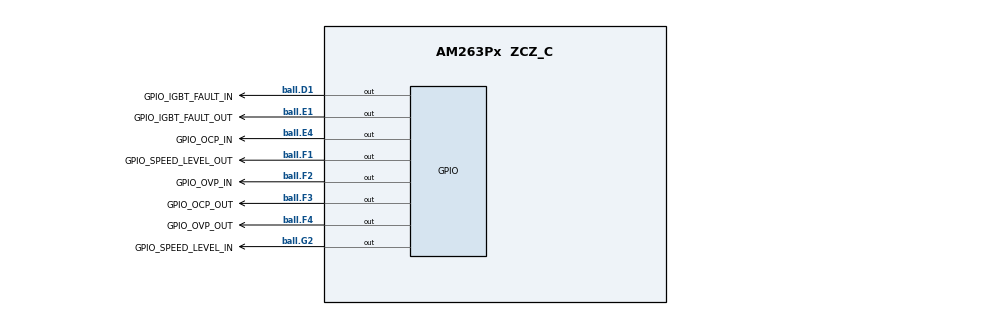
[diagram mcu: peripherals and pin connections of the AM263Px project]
/**
 * These arguments were used when this file was generated. They will be automatically applied on subsequent loads
 * via the GUI or CLI. Run CLI with '--help' for additional information on how to override these arguments.
 * @cliArgs --device "AM263Px" --package "ZCZ_C" --part "AM263P1" --context "r5fss0-0" --product "MCU_PLUS_SDK@07.03.01"
 * @versions {"tool":"1.15.0+2826"}
 */

/**
 * Import the modules used in this configuration.
 */
const epwm       = scripting.addModule("/drivers/epwm/epwm", {}, false);
const epwm1      = epwm.addInstance();
const epwm2      = epwm.addInstance();
const epwm3      = epwm.addInstance();
const gpio       = scripting.addModule("/drivers/gpio/gpio", {}, false);
const gpio1      = gpio.addInstance();
const gpio2      = gpio.addInstance();
const gpio3      = gpio.addInstance();
const gpio4      = gpio.addInstance();
const gpio5      = gpio.addInstance();
const gpio6      = gpio.addInstance();
const gpio7      = gpio.addInstance();
const gpio8      = gpio.addInstance();
const debug_log  = scripting.addModule("/kernel/dpl/debug_log");
const mpu_armv7  = scripting.addModule("/kernel/dpl/mpu_armv7", {}, false);
const mpu_armv71 = mpu_armv7.addInstance();
const mpu_armv72 = mpu_armv7.addInstance();
const mpu_armv73 = mpu_armv7.addInstance();
const mpu_armv74 = mpu_armv7.addInstance();
const epwm_xbar  = scripting.addModule("/xbar/epwm_xbar/epwm_xbar", {}, false);
const epwm_xbar1 = epwm_xbar.addInstance();
const epwm_xbar2 = epwm_xbar.addInstance();
const epwm_xbar3 = epwm_xbar.addInstance();
const epwm_xbar4 = epwm_xbar.addInstance();
const epwm_xbar5 = epwm_xbar.addInstance();
const epwm_xbar6 = epwm_xbar.addInstance();
const epwm_xbar7 = epwm_xbar.addInstance();
const epwm_xbar8 = epwm_xbar.addInstance();
const int_xbar   = scripting.addModule("/xbar/int_xbar/int_xbar", {}, false);
const int_xbar1  = int_xbar.addInstance();

/**
 * Write custom configuration values to the imported modules.
 */
epwm1.epwmTimebase_emulationMode                               = "EPWM_EMULATION_FREE_RUN";
epwm1.epwmTimebase_period                                      = 10000;
epwm1.epwmTimebase_counterMode                                 = "EPWM_COUNTER_MODE_UP";
epwm1.epwmTimebase_syncOutPulseMode                            = ["EPWM_SYNC_OUT_PULSE_ON_ALL"];
epwm1.epwmCounterCompare_cmpA                                  = 7000;
epwm1.epwmCounterCompare_cmpB                                  = 7000;
epwm1.epwmActionQualifier_EPWM_AQ_OUTPUT_A_usedEvents          = ["EPWM_AQ_OUTPUT_ON_TIMEBASE_UP_CMPA","EPWM_AQ_OUTPUT_ON_TIMEBASE_ZERO"];
epwm1.epwmActionQualifier_EPWM_AQ_OUTPUT_B_usedEvents          = ["EPWM_AQ_OUTPUT_ON_TIMEBASE_UP_CMPB","EPWM_AQ_OUTPUT_ON_TIMEBASE_ZERO"];
epwm1.epwmActionQualifier_EPWM_AQ_OUTPUT_A_ON_TIMEBASE_ZERO    = "EPWM_AQ_OUTPUT_HIGH";
epwm1.epwmActionQualifier_EPWM_AQ_OUTPUT_A_ON_TIMEBASE_UP_CMPA = "EPWM_AQ_OUTPUT_LOW";
epwm1.epwmActionQualifier_EPWM_AQ_OUTPUT_B_ON_TIMEBASE_ZERO    = "EPWM_AQ_OUTPUT_LOW";
epwm1.epwmActionQualifier_EPWM_AQ_OUTPUT_B_ON_TIMEBASE_UP_CMPB = "EPWM_AQ_OUTPUT_HIGH";
epwm1.epwmEventTrigger_enableInterrupt                         = true;
epwm1.epwmEventTrigger_interruptEventCount                     = "1";
epwm1.epwmTripZone_EPWM_TZ_ACTION_EVENT_DCAEVT1                = "EPWM_TZ_ACTION_HIGH";
epwm1.epwmTripZone_EPWM_TZ_ACTION_EVENT_DCAEVT2                = "EPWM_TZ_ACTION_LOW";
epwm1.epwmTripZone_EPWM_TZ_ACTION_EVENT_DCBEVT1                = "EPWM_TZ_ACTION_HIGH";
epwm1.epwmTripZone_EPWM_TZ_ACTION_EVENT_DCBEVT2                = "EPWM_TZ_ACTION_LOW";
epwm1.epwmDigitalCompare_EPWM_TZ_DC_OUTPUT_A1                  = "EPWM_TZ_EVENT_DCXH_HIGH";
epwm1.epwmDigitalCompare_EPWM_TZ_DC_OUTPUT_A2                  = "EPWM_TZ_EVENT_DCXL_HIGH";
epwm1.epwmDigitalCompare_EPWM_TZ_DC_OUTPUT_B1                  = "EPWM_TZ_EVENT_DCXH_HIGH";
epwm1.epwmDigitalCompare_EPWM_TZ_DC_OUTPUT_B2                  = "EPWM_TZ_EVENT_DCXL_HIGH";
epwm1.epwmDigitalCompare_EPWM_DC_TYPE_DCAH                     = "EPWM_DC_TRIP_TRIPIN5";
epwm1.epwmDigitalCompare_EPWM_DC_TYPE_DCAL                     = "EPWM_DC_TRIP_TRIPIN6";
epwm1.epwmDigitalCompare_EPWM_DC_TYPE_DCBH                     = "EPWM_DC_TRIP_TRIPIN7";
epwm1.epwmDigitalCompare_EPWM_DC_TYPE_DCBL                     = "EPWM_DC_TRIP_TRIPIN8";
epwm1.$name                                                    = "CONFIG_PWM0";
epwm1.epwmDeadband_polarityFED                                 = "EPWM_DB_POLARITY_ACTIVE_LOW";
epwm1.epwmDeadband_enableRED                                   = true;
epwm1.epwmDeadband_enableFED                                   = true;
epwm1.epwmDeadband_delayRED                                    = 100;
epwm1.epwmDeadband_delayFED                                    = 100;
epwm1.EPWM.$assign                                             = "EPWM0";

epwm2.$name                                                    = "CONFIG_PWM1";
epwm2.epwmTimebase_counterMode                                 = "EPWM_COUNTER_MODE_UP";
epwm2.epwmTimebase_period                                      = 10000;
epwm2.epwmCounterCompare_cmpA                                  = 7000;
epwm2.epwmCounterCompare_cmpB                                  = 7000;
epwm2.epwmActionQualifier_EPWM_AQ_OUTPUT_A_usedEvents          = ["EPWM_AQ_OUTPUT_ON_TIMEBASE_UP_CMPA","EPWM_AQ_OUTPUT_ON_TIMEBASE_ZERO"];
epwm2.epwmActionQualifier_EPWM_AQ_OUTPUT_B_usedEvents          = ["EPWM_AQ_OUTPUT_ON_TIMEBASE_UP_CMPB","EPWM_AQ_OUTPUT_ON_TIMEBASE_ZERO"];
epwm2.epwmActionQualifier_EPWM_AQ_OUTPUT_A_ON_TIMEBASE_ZERO    = "EPWM_AQ_OUTPUT_HIGH";
epwm2.epwmActionQualifier_EPWM_AQ_OUTPUT_A_ON_TIMEBASE_UP_CMPA = "EPWM_AQ_OUTPUT_LOW";
epwm2.epwmActionQualifier_EPWM_AQ_OUTPUT_B_ON_TIMEBASE_ZERO    = "EPWM_AQ_OUTPUT_LOW";
epwm2.epwmActionQualifier_EPWM_AQ_OUTPUT_B_ON_TIMEBASE_UP_CMPB = "EPWM_AQ_OUTPUT_HIGH";
epwm2.epwmTripZone_EPWM_TZ_ACTION_EVENT_DCAEVT1                = "EPWM_TZ_ACTION_HIGH";
epwm2.epwmTripZone_EPWM_TZ_ACTION_EVENT_DCAEVT2                = "EPWM_TZ_ACTION_LOW";
epwm2.epwmTripZone_EPWM_TZ_ACTION_EVENT_DCBEVT1                = "EPWM_TZ_ACTION_HIGH";
epwm2.epwmTripZone_EPWM_TZ_ACTION_EVENT_DCBEVT2                = "EPWM_TZ_ACTION_LOW";
epwm2.epwmDigitalCompare_EPWM_TZ_DC_OUTPUT_A1                  = "EPWM_TZ_EVENT_DCXH_HIGH";
epwm2.epwmDigitalCompare_EPWM_TZ_DC_OUTPUT_A2                  = "EPWM_TZ_EVENT_DCXL_HIGH";
epwm2.epwmDigitalCompare_EPWM_TZ_DC_OUTPUT_B1                  = "EPWM_TZ_EVENT_DCXH_HIGH";
epwm2.epwmDigitalCompare_EPWM_TZ_DC_OUTPUT_B2                  = "EPWM_TZ_EVENT_DCXL_HIGH";
epwm2.epwmDigitalCompare_EPWM_DC_TYPE_DCAH                     = "EPWM_DC_TRIP_TRIPIN5";
epwm2.epwmDigitalCompare_EPWM_DC_TYPE_DCAL                     = "EPWM_DC_TRIP_TRIPIN6";
epwm2.epwmDigitalCompare_EPWM_DC_TYPE_DCBH                     = "EPWM_DC_TRIP_TRIPIN7";
epwm2.epwmDigitalCompare_EPWM_DC_TYPE_DCBL                     = "EPWM_DC_TRIP_TRIPIN8";
epwm2.epwmDeadband_polarityFED                                 = "EPWM_DB_POLARITY_ACTIVE_LOW";
epwm2.epwmDeadband_enableRED                                   = true;
epwm2.epwmDeadband_enableFED                                   = true;
epwm2.epwmDeadband_delayRED                                    = 100;
epwm2.epwmDeadband_delayFED                                    = 100;
epwm2.EPWM.$assign                                             = "EPWM1";

epwm3.$name                                                    = "CONFIG_PWM2";
epwm3.epwmTimebase_counterMode                                 = "EPWM_COUNTER_MODE_UP";
epwm3.epwmTimebase_period                                      = 10000;
epwm3.epwmCounterCompare_cmpA                                  = 7000;
epwm3.epwmCounterCompare_cmpB                                  = 7000;
epwm3.epwmActionQualifier_EPWM_AQ_OUTPUT_A_usedEvents          = ["EPWM_AQ_OUTPUT_ON_TIMEBASE_UP_CMPA","EPWM_AQ_OUTPUT_ON_TIMEBASE_ZERO"];
epwm3.epwmActionQualifier_EPWM_AQ_OUTPUT_B_usedEvents          = ["EPWM_AQ_OUTPUT_ON_TIMEBASE_UP_CMPB","EPWM_AQ_OUTPUT_ON_TIMEBASE_ZERO"];
epwm3.epwmActionQualifier_EPWM_AQ_OUTPUT_A_ON_TIMEBASE_ZERO    = "EPWM_AQ_OUTPUT_HIGH";
epwm3.epwmActionQualifier_EPWM_AQ_OUTPUT_A_ON_TIMEBASE_UP_CMPA = "EPWM_AQ_OUTPUT_LOW";
epwm3.epwmActionQualifier_EPWM_AQ_OUTPUT_B_ON_TIMEBASE_ZERO    = "EPWM_AQ_OUTPUT_LOW";
epwm3.epwmActionQualifier_EPWM_AQ_OUTPUT_B_ON_TIMEBASE_UP_CMPB = "EPWM_AQ_OUTPUT_HIGH";
epwm3.epwmTripZone_EPWM_TZ_ACTION_EVENT_DCAEVT1                = "EPWM_TZ_ACTION_HIGH";
epwm3.epwmTripZone_EPWM_TZ_ACTION_EVENT_DCAEVT2                = "EPWM_TZ_ACTION_LOW";
epwm3.epwmTripZone_EPWM_TZ_ACTION_EVENT_DCBEVT1                = "EPWM_TZ_ACTION_HIGH";
epwm3.epwmTripZone_EPWM_TZ_ACTION_EVENT_DCBEVT2                = "EPWM_TZ_ACTION_LOW";
epwm3.epwmDigitalCompare_EPWM_TZ_DC_OUTPUT_A1                  = "EPWM_TZ_EVENT_DCXH_HIGH";
epwm3.epwmDigitalCompare_EPWM_TZ_DC_OUTPUT_A2                  = "EPWM_TZ_EVENT_DCXL_HIGH";
epwm3.epwmDigitalCompare_EPWM_TZ_DC_OUTPUT_B1                  = "EPWM_TZ_EVENT_DCXH_HIGH";
epwm3.epwmDigitalCompare_EPWM_TZ_DC_OUTPUT_B2                  = "EPWM_TZ_EVENT_DCXL_HIGH";
epwm3.epwmDigitalCompare_EPWM_DC_TYPE_DCAH                     = "EPWM_DC_TRIP_TRIPIN5";
epwm3.epwmDigitalCompare_EPWM_DC_TYPE_DCAL                     = "EPWM_DC_TRIP_TRIPIN6";
epwm3.epwmDigitalCompare_EPWM_DC_TYPE_DCBH                     = "EPWM_DC_TRIP_TRIPIN7";
epwm3.epwmDigitalCompare_EPWM_DC_TYPE_DCBL                     = "EPWM_DC_TRIP_TRIPIN8";
epwm3.epwmDeadband_polarityFED                                 = "EPWM_DB_POLARITY_ACTIVE_LOW";
epwm3.epwmDeadband_enableRED                                   = true;
epwm3.epwmDeadband_enableFED                                   = true;
epwm3.epwmDeadband_delayRED                                    = 100;
epwm3.epwmDeadband_delayFED                                    = 100;
epwm3.EPWM.$assign                                             = "EPWM2";

gpio1.$name                = "GPIO_IGBT_FAULT_IN";
gpio1.GPIO.gpioPin.$assign = "ball.D1";

gpio2.$name                = "GPIO_OVP_IN";
gpio2.GPIO.gpioPin.$assign = "ball.F2";

gpio3.pinDir               = "OUTPUT";
gpio3.$name                = "GPIO_IGBT_FAULT_OUT";
gpio3.GPIO.gpioPin.$assign = "ball.E1";

gpio4.pinDir               = "OUTPUT";
gpio4.$name                = "GPIO_OVP_OUT";
gpio4.GPIO.gpioPin.$assign = "ball.F4";

gpio5.$name                = "GPIO_OCP_IN";
gpio5.GPIO.gpioPin.$assign = "ball.E4";

gpio6.$name                = "GPIO_SPEED_LEVEL_IN";
gpio6.GPIO.gpioPin.$assign = "ball.G2";

gpio7.pinDir               = "OUTPUT";
gpio7.$name                = "GPIO_OCP_OUT";
gpio7.GPIO.gpioPin.$assign = "ball.F3";

gpio8.pinDir               = "OUTPUT";
gpio8.$name                = "GPIO_SPEED_LEVEL_OUT";
gpio8.GPIO.gpioPin.$assign = "ball.F1";

debug_log.enableUartLog            = true;
debug_log.uartLog.$name            = "CONFIG_UART0";
debug_log.uartLog.UART.RXD.$assign = "ball.A7";
debug_log.uartLog.UART.TXD.$assign = "ball.A6";

mpu_armv71.$name             = "CONFIG_MPU_REGION0";
mpu_armv71.size              = 31;
mpu_armv71.attributes        = "Device";
mpu_armv71.accessPermissions = "Supervisor RD+WR, User RD";
mpu_armv71.allowExecute      = false;

mpu_armv72.$name             = "CONFIG_MPU_REGION1";
mpu_armv72.size              = 15;
mpu_armv72.accessPermissions = "Supervisor RD+WR, User RD";

mpu_armv73.$name             = "CONFIG_MPU_REGION2";
mpu_armv73.baseAddr          = 0x80000;
mpu_armv73.size              = 15;
mpu_armv73.accessPermissions = "Supervisor RD+WR, User RD";

mpu_armv74.$name             = "CONFIG_MPU_REGION3";
mpu_armv74.accessPermissions = "Supervisor RD+WR, User RD";
mpu_armv74.baseAddr          = 0x70000000;
mpu_armv74.size              = 21;

epwm_xbar1.$name                 = "CONFIG_EPWM_XBAR0_INPUTXBAR_TO_ICSSGPI";
epwm_xbar1.xbarOutput            = ["GPIO51"];
epwm_xbar1["xbarConfig-0"].$name = "CONFIG_INPUT_XBAR0";

epwm_xbar2.instance                 = "EPWM_XBAR_1";
epwm_xbar2.$name                    = "CONFIG_EPWM_XBAR1_INPUTXBAR_TO_ICSSGPI";
epwm_xbar2.xbarOutput               = ["GPIO52"];
epwm_xbar2["xbarConfig-0"].$name    = "CONFIG_INPUT_XBAR1";
epwm_xbar2["xbarConfig-0"].instance = "INPUT_XBAR_1";

epwm_xbar3.instance                 = "EPWM_XBAR_2";
epwm_xbar3.$name                    = "CONFIG_EPWM_XBAR2_INPUTXBAR_TO_ICSSGPI";
epwm_xbar3.xbarOutput               = ["GPIO53"];
epwm_xbar3["xbarConfig-0"].$name    = "CONFIG_INPUT_XBAR2";
epwm_xbar3["xbarConfig-0"].instance = "INPUT_XBAR_2";

epwm_xbar4.instance                 = "EPWM_XBAR_3";
epwm_xbar4.$name                    = "CONFIG_EPWM_XBAR3_INPUTXBAR_TO_ICSSGPI";
epwm_xbar4.xbarOutput               = ["GPIO54"];
epwm_xbar4["xbarConfig-0"].$name    = "CONFIG_INPUT_XBAR3";
epwm_xbar4["xbarConfig-0"].instance = "INPUT_XBAR_3";

epwm_xbar5.xbarOutput               = ["ICSSGPO0_PORT0"];
epwm_xbar5.instance                 = "EPWM_XBAR_4";
epwm_xbar5.$name                    = "CONFIG_EPWM_XBAR4_INPUTXBAR_TO_EPWM";
epwm_xbar5["xbarConfig-0"].instance = "INPUT_XBAR_4";
epwm_xbar5["xbarConfig-0"].$name    = "CONFIG_INPUT_XBAR4_ICSSGPO_TO_PWMXBAR";

epwm_xbar6.xbarOutput               = ["ICSSGPO1_PORT0"];
epwm_xbar6.instance                 = "EPWM_XBAR_5";
epwm_xbar6.$name                    = "CONFIG_EPWM_XBAR5_INPUTXBAR_TO_EPWM";
epwm_xbar6["xbarConfig-0"].instance = "INPUT_XBAR_5";
epwm_xbar6["xbarConfig-0"].$name    = "CONFIG_INPUT_XBAR5_ICSSGPO_TO_PWMXBAR";

epwm_xbar7.xbarOutput               = ["ICSSGPO2_PORT0"];
epwm_xbar7.instance                 = "EPWM_XBAR_6";
epwm_xbar7.$name                    = "CONFIG_EPWM_XBAR6_INPUTXBAR_TO_EPWM";
epwm_xbar7["xbarConfig-0"].instance = "INPUT_XBAR_6";
epwm_xbar7["xbarConfig-0"].$name    = "CONFIG_INPUT_XBAR6_ICSSGPO_TO_PWMXBAR";

epwm_xbar8.xbarOutput               = ["ICSSGPO3_PORT0"];
epwm_xbar8.instance                 = "EPWM_XBAR_7";
epwm_xbar8.$name                    = "CONFIG_EPWM_XBAR7_INPUTXBAR_TO_EPWM";
epwm_xbar8["xbarConfig-0"].instance = "INPUT_XBAR_7";
epwm_xbar8["xbarConfig-0"].$name    = "CONFIG_INPUT_XBAR7_ICSSGPO_TO_PWMXBAR";

int_xbar1.$name      = "CONFIG_INT_XBAR0";
int_xbar1.xbarOutput = ["EPWM9_INT"];

/**
 * Pinmux solution for unlocked pins/peripherals. This ensures that minor changes to the automatic solver in a future
 * version of the tool will not impact the pinmux you originally saw.  These lines can be completely deleted in order to
 * re-solve from scratch.
 */
epwm1.EPWM.A.$suggestSolution           = "ball.B2";
epwm1.EPWM.B.$suggestSolution           = "ball.B1";
epwm2.EPWM.A.$suggestSolution           = "ball.D3";
epwm2.EPWM.B.$suggestSolution           = "ball.D2";
epwm3.EPWM.A.$suggestSolution           = "ball.C2";
epwm3.EPWM.B.$suggestSolution           = "ball.C1";
gpio1.GPIO.$suggestSolution             = "GPIO";
gpio2.GPIO.$suggestSolution             = "GPIO";
gpio3.GPIO.$suggestSolution             = "GPIO";
gpio4.GPIO.$suggestSolution             = "GPIO";
gpio5.GPIO.$suggestSolution             = "GPIO";
gpio6.GPIO.$suggestSolution             = "GPIO";
gpio7.GPIO.$suggestSolution             = "GPIO";
gpio8.GPIO.$suggestSolution             = "GPIO";
debug_log.uartLog.UART.$suggestSolution = "UART0";
